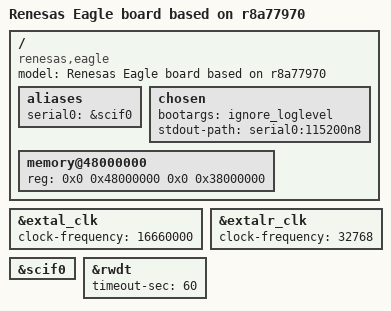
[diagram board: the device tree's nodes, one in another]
/*
 * Device Tree Source for the Eagle board
 *
 * Copyright (C) 2016 Renesas Electronics Corp.
 * Copyright (C) 2017 Glider bvba
 *
 * This file is licensed under the terms of the GNU General Public License
 * version 2.  This program is licensed "as is" without any warranty of any
 * kind, whether express or implied.
 */

/dts-v1/;
#include "r8a77970.dtsi"

/ {
	model = "Renesas Eagle board based on r8a77970";
	compatible = "renesas,eagle", "renesas,r8a77970";

	aliases {
		serial0 = &scif0;
	};

	chosen {
		bootargs = "ignore_loglevel";
		stdout-path = "serial0:115200n8";
	};

	memory@48000000 {
		device_type = "memory";
		/* first 128MB is reserved for secure area. */
		reg = <0x0 0x48000000 0x0 0x38000000>;
	};
};

&extal_clk {
	clock-frequency = <16660000>;
};

&extalr_clk {
	clock-frequency = <32768>;
};

&scif0 {
	status = "okay";
};

&rwdt {
	timeout-sec = <60>;
	status = "okay";
};
